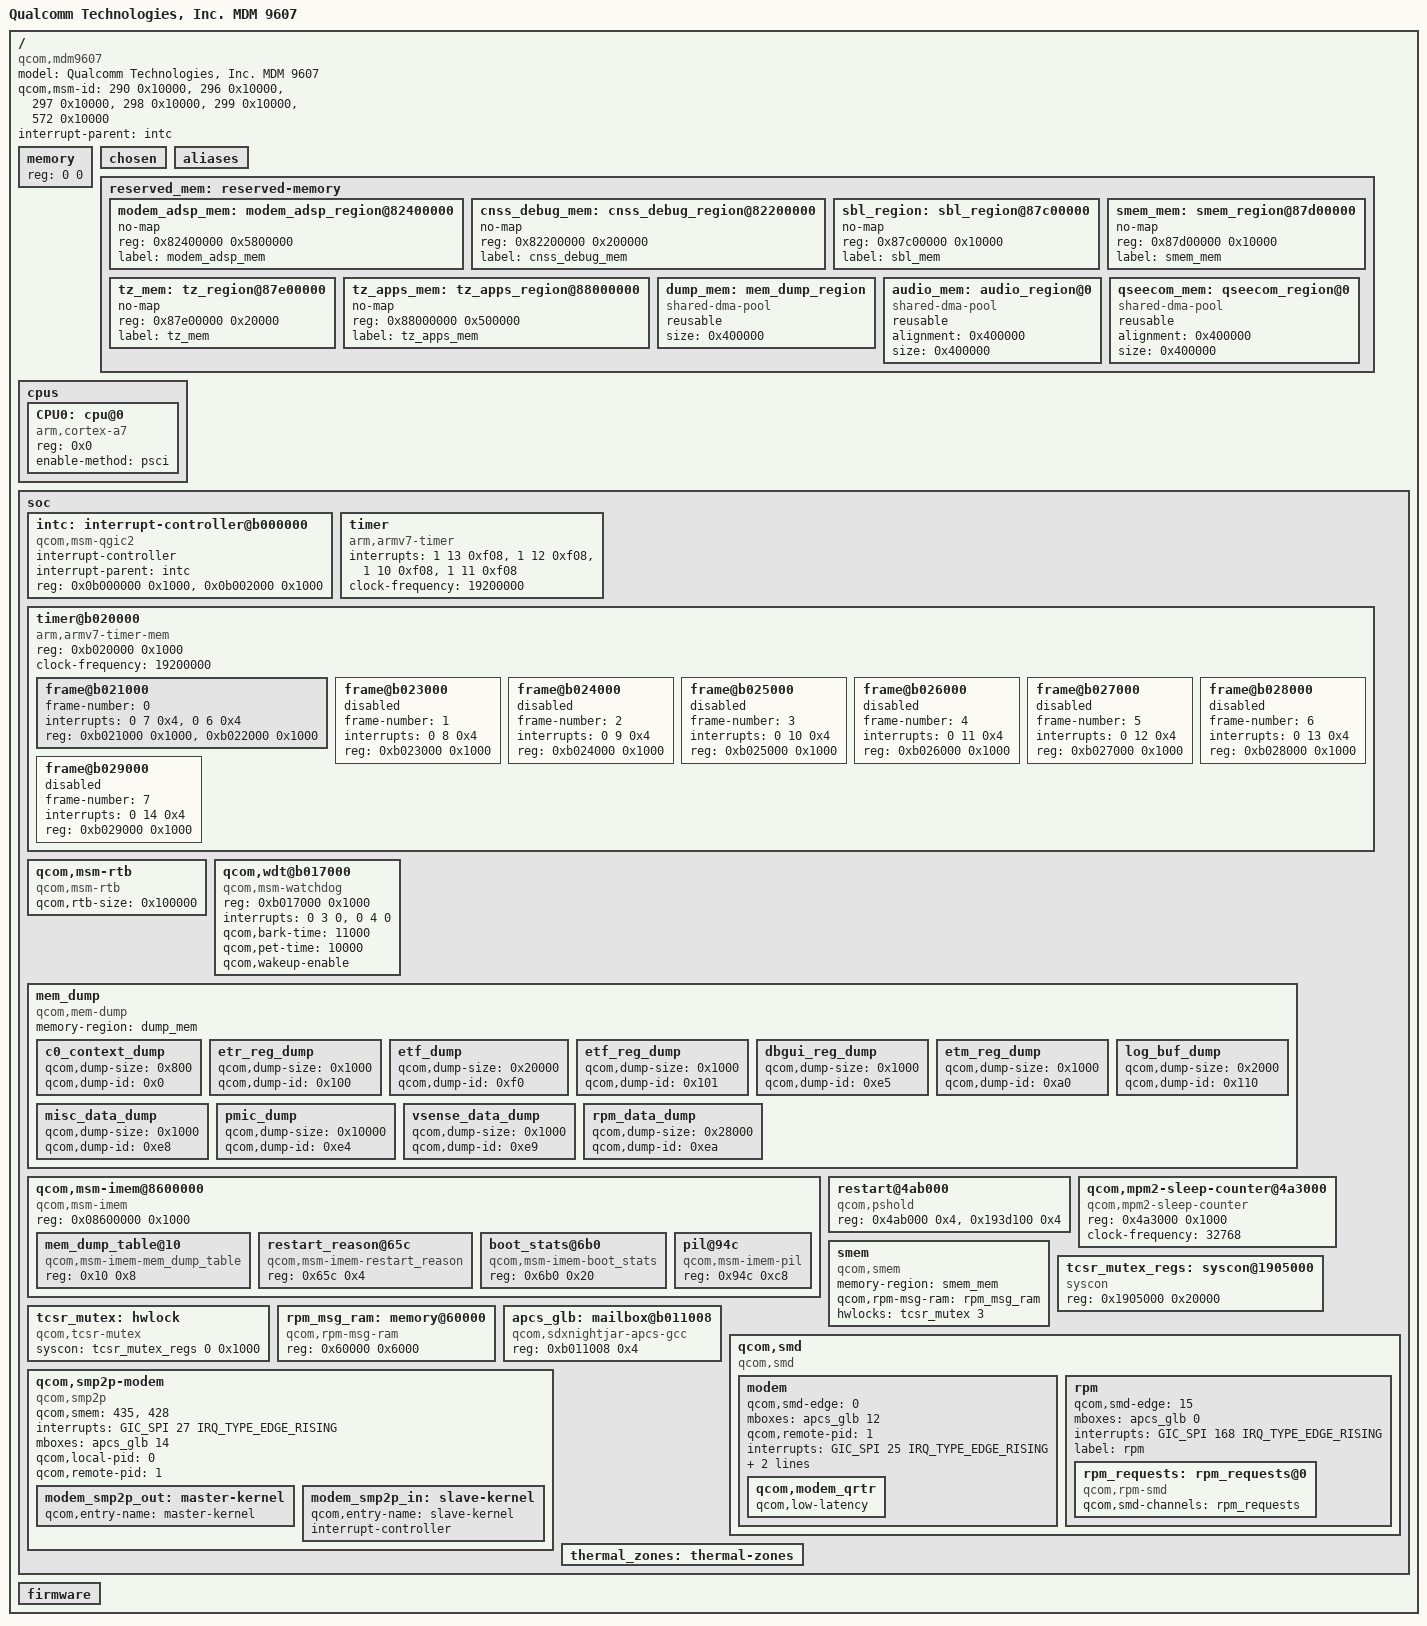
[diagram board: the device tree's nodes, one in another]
#include <dt-bindings/clock/qcom,rpmh.h>
#include <dt-bindings/interrupt-controller/arm-gic.h>
#include <dt-bindings/soc/qcom,rpmh-rsc.h>

/ {
	#address-cells = <1>;
	#size-cells = <1>;
	model = "Qualcomm Technologies, Inc. MDM 9607";
	compatible = "qcom,mdm9607";
	qcom,msm-id = <290 0x10000>, <296 0x10000>, <297 0x10000>,
		      <298 0x10000>, <299 0x10000>, <572 0x10000>;
	interrupt-parent = <&intc>;

	memory { device_type = "memory"; reg = <0 0>; };

	chosen: chosen { };

	aliases {
	};

	reserved_mem: reserved-memory {
		#address-cells = <1>;
		#size-cells = <1>;
		ranges;

		modem_adsp_mem: modem_adsp_region@82400000 {
			no-map;
			reg = <0x82400000 0x5800000>;
			label = "modem_adsp_mem";
		};

		cnss_debug_mem: cnss_debug_region@82200000 {
			no-map;
			reg = <0x82200000 0x200000>;
			label = "cnss_debug_mem";
		};

		sbl_region: sbl_region@87c00000 {
			no-map;
			reg = <0x87c00000 0x10000>;
			label = "sbl_mem";
		};

		smem_mem: smem_region@87d00000 {
			no-map;
			reg = <0x87d00000 0x10000>;
			label = "smem_mem";
		};

		tz_mem: tz_region@87e00000 {
			no-map;
			reg = <0x87e00000 0x20000>;
			label = "tz_mem";
		};

		tz_apps_mem: tz_apps_region@88000000 {
			no-map;
			reg = <0x88000000 0x500000>;
			label = "tz_apps_mem";
		};

		dump_mem: mem_dump_region {
			compatible = "shared-dma-pool";
			reusable;
			size = <0x400000>;
		};

		audio_mem: audio_region@0 {
			compatible = "shared-dma-pool";
			reusable;
			alignment = <0x400000>;
			size = <0x400000>;
		};

		qseecom_mem: qseecom_region@0 {
			compatible = "shared-dma-pool";
			reusable;
			alignment = <0x400000>;
			size = <0x400000>;
			status = "ok";
		};
	};

	cpus {
		#size-cells = <0>;
		#address-cells = <1>;

		CPU0: cpu@0 {
			device_type = "cpu";
			compatible = "arm,cortex-a7";
			reg = <0x0>;
			enable-method = "psci";
			#cooling-cells = <2>;
		};
	};

	soc: soc { };

	firmware: firmware {};
};

#include "mdm9x07-pinctrl.dtsi"
#include "mdm9x07-ion.dtsi"

&soc {
	#address-cells = <1>;
	#size-cells = <1>;
	ranges;

	intc: interrupt-controller@b000000 {
		compatible = "qcom,msm-qgic2";
		interrupt-controller;
		interrupt-parent = <&intc>;
		#interrupt-cells = <3>;
		reg = <0x0b000000 0x1000>,
		      <0x0b002000 0x1000>;
	};

	timer {
		compatible = "arm,armv7-timer";
		interrupts = <1 13 0xf08>,
			     <1 12 0xf08>,
			     <1 10 0xf08>,
			     <1 11 0xf08>;
		clock-frequency = <19200000>;
	};

	timer@b020000 {
		#address-cells = <1>;
		#size-cells = <1>;
		ranges;
		compatible = "arm,armv7-timer-mem";
		reg = <0xb020000 0x1000>;
		clock-frequency = <19200000>;

		frame@b021000 {
			frame-number = <0>;
			interrupts = <0 7 0x4>,
				     <0 6 0x4>;
			reg = <0xb021000 0x1000>,
			      <0xb022000 0x1000>;
		};

		frame@b023000 {
			frame-number = <1>;
			interrupts = <0 8 0x4>;
			reg = <0xb023000 0x1000>;
			status = "disabled";
		};

		frame@b024000 {
			frame-number = <2>;
			interrupts = <0 9 0x4>;
			reg = <0xb024000 0x1000>;
			status = "disabled";
		};

		frame@b025000 {
			frame-number = <3>;
			interrupts = <0 10 0x4>;
			reg = <0xb025000 0x1000>;
			status = "disabled";
		};

		frame@b026000 {
			frame-number = <4>;
			interrupts = <0 11 0x4>;
			reg = <0xb026000 0x1000>;
			status = "disabled";
		};

		frame@b027000 {
			frame-number = <5>;
			interrupts = <0 12 0x4>;
			reg = <0xb027000 0x1000>;
			status = "disabled";
		};

		frame@b028000 {
			frame-number = <6>;
			interrupts = <0 13 0x4>;
			reg = <0xb028000 0x1000>;
			status = "disabled";
		};

		frame@b029000 {
			frame-number = <7>;
			interrupts = <0 14 0x4>;
			reg = <0xb029000 0x1000>;
			status = "disabled";
		};
	};

	qcom,msm-rtb {
		compatible = "qcom,msm-rtb";
		qcom,rtb-size = <0x100000>;
	};

	qcom,wdt@b017000 {
		compatible = "qcom,msm-watchdog";
		reg = <0xb017000 0x1000>;
		reg-names = "wdt-base";
		interrupts = <0 3 0>, <0 4 0>;
		qcom,bark-time = <11000>;
		qcom,pet-time = <10000>;
		qcom,wakeup-enable;
	};

	mem_dump {
		compatible = "qcom,mem-dump";
		memory-region = <&dump_mem>;

		c0_context_dump {
			qcom,dump-size = <0x800>;
			qcom,dump-id = <0x0>;
		};

		etr_reg_dump {
			qcom,dump-size = <0x1000>;
			qcom,dump-id = <0x100>;
		};

		etf_dump {
			qcom,dump-size = <0x20000>;
			qcom,dump-id = <0xf0>;
		};

		etf_reg_dump {
			qcom,dump-size = <0x1000>;
			qcom,dump-id = <0x101>;
		};

		dbgui_reg_dump {
			qcom,dump-size = <0x1000>;
			qcom,dump-id = <0xe5>;
		};

		etm_reg_dump {
			qcom,dump-size = <0x1000>;
			qcom,dump-id = <0xa0>;
		};

		log_buf_dump {
			qcom,dump-size = <0x2000>;
			qcom,dump-id = <0x110>;
		};

		misc_data_dump {
			qcom,dump-size = <0x1000>;
			qcom,dump-id = <0xe8>;
		};

		pmic_dump {
			qcom,dump-size = <0x10000>;
			qcom,dump-id = <0xe4>;
		};

		vsense_data_dump {
			qcom,dump-size = <0x1000>;
			qcom,dump-id = <0xe9>;
		};

		rpm_data_dump {
			qcom,dump-size = <0x28000>;
			qcom,dump-id = <0xea>;
		};
	};

	qcom,msm-imem@8600000 {
		compatible = "qcom,msm-imem";
		reg = <0x08600000 0x1000>; /* Address and size of IMEM */
		ranges = <0x0 0x08600000 0x1000>;
		#address-cells = <1>;
		#size-cells = <1>;

		mem_dump_table@10 {
			compatible = "qcom,msm-imem-mem_dump_table";
			reg = <0x10 0x8>;
		};

		restart_reason@65c {
			compatible = "qcom,msm-imem-restart_reason";
			reg = <0x65c 0x4>;
		};

		boot_stats@6b0 {
			compatible = "qcom,msm-imem-boot_stats";
			reg = <0x6b0 0x20>;
		};

		pil@94c {
			compatible = "qcom,msm-imem-pil";
			reg = <0x94c 0xc8>;
		};
	};

	restart@4ab000 {
		compatible = "qcom,pshold";
		reg = <0x4ab000 0x4>,
		    <0x193d100 0x4>;
		reg-names = "pshold-base", "tcsr-boot-misc-detect";
	};

	qcom,mpm2-sleep-counter@4a3000 {
		compatible = "qcom,mpm2-sleep-counter";
		reg = <0x4a3000 0x1000>;
		clock-frequency = <32768>;
	};

	smem {
		compatible = "qcom,smem";
		memory-region = <&smem_mem>;
		qcom,rpm-msg-ram = <&rpm_msg_ram>;
		hwlocks = <&tcsr_mutex 3>;
	};

	tcsr_mutex_regs: syscon@1905000 {
		compatible = "syscon";
		reg = <0x1905000 0x20000>;
	};

	tcsr_mutex: hwlock {
		compatible = "qcom,tcsr-mutex";
		syscon = <&tcsr_mutex_regs 0 0x1000>;
		#hwlock-cells = <1>;
	};

	rpm_msg_ram: memory@60000 {
		compatible = "qcom,rpm-msg-ram";
		reg = <0x60000 0x6000>;
	};

	apcs_glb: mailbox@b011008 {
		compatible = "qcom,sdxnightjar-apcs-gcc";
		reg = <0xb011008 0x4>;
		#mbox-cells = <1>;
	};

	qcom,smd {
		compatible = "qcom,smd";

		modem {
			qcom,smd-edge = <0>;
			mboxes = <&apcs_glb 12>;
			qcom,remote-pid = <1>;
			interrupts = <GIC_SPI 25 IRQ_TYPE_EDGE_RISING>;
			label = "mpss";

			qcom,smd-channels = "IPCRTR";
			qcom,modem_qrtr {
			qcom,low-latency;
			};
		};

		rpm {
			qcom,smd-edge = <15>;
			mboxes = <&apcs_glb 0>;
			interrupts = <GIC_SPI 168 IRQ_TYPE_EDGE_RISING>;
			label = "rpm";

			rpm_requests: rpm_requests@0 {
				compatible = "qcom,rpm-smd";
				qcom,smd-channels = "rpm_requests";
			};
		};
	};

	qcom,smp2p-modem {
		compatible = "qcom,smp2p";
		qcom,smem = <435>, <428>;
		interrupts = <GIC_SPI 27 IRQ_TYPE_EDGE_RISING>;
		mboxes = <&apcs_glb 14>;
		qcom,local-pid = <0>;
		qcom,remote-pid = <1>;

		modem_smp2p_out: master-kernel {
			qcom,entry-name = "master-kernel";
			#qcom,smem-state-cells = <1>;
		};

		modem_smp2p_in: slave-kernel {
			qcom,entry-name = "slave-kernel";
			interrupt-controller;
			#interrupt-cells = <2>;
		};
	};

	thermal_zones: thermal-zones {};
};

#include "pm8019-rpm-regulator.dtsi"
#include "mdm9607-regulator.dtsi"
#include "mdm9607-thermal.dtsi"
